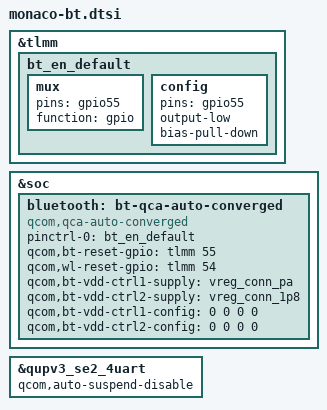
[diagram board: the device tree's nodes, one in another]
#include <dt-bindings/interconnect/qcom,monaco_auto.h>

&tlmm {
	bt_en_default: bt_en_default {
		mux {
			pins = "gpio55";
			function = "gpio";
		};

		config {
			pins = "gpio55";
			output-low;
			bias-pull-down;
		};
	};
};

&soc {
	bluetooth: bt-qca-auto-converged {
		compatible = "qcom,qca-auto-converged";
		pinctrl-names = "default";
		pinctrl-0 = <&bt_en_default>;
		/* BT_EN */
		qcom,bt-reset-gpio = <&tlmm 55 0>;
		/* WL_EN */
		qcom,wl-reset-gpio = <&tlmm 54 0>;
		/* PWR_CTR1_VDD_PA */
		qcom,bt-vdd-ctrl1-supply = <&vreg_conn_pa>;
		qcom,bt-vdd-ctrl2-supply = <&vreg_conn_1p8>;

		/* <vol_min, vol_max, load_curr, is_retention_supp> */
		qcom,bt-vdd-ctrl1-config = <0 0 0 0>;
		qcom,bt-vdd-ctrl2-config = <0 0 0 0>;
	};
};

&qupv3_se2_4uart {
	status = "ok";
	qcom,auto-suspend-disable;
};
